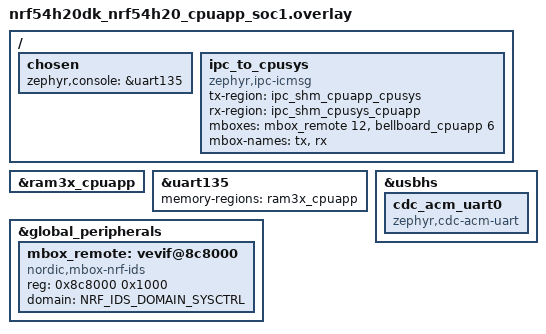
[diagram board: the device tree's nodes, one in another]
/*
 * Copyright (c) 2022 Nordic Semiconductor ASA
 *
 * SPDX-License-Identifier: LicenseRef-BSD-5-Clause-Nordic
 */

#include <common/nordic_nrf_next/nrfx_ram3x_dma.dtsi>

/{
	chosen {
		zephyr,console = &uart135;
	};

	ipc_to_cpusys: ipc_to_cpusys {
		compatible = "zephyr,ipc-icmsg";
		tx-region = <&ipc_shm_cpuapp_cpusys>;
		rx-region = <&ipc_shm_cpusys_cpuapp>;
		mboxes = <&mbox_remote 12>,
			 <&bellboard_cpuapp 6>;
		mbox-names = "tx", "rx";
		status = "okay";
	};
};

&ram3x_cpuapp {
	status = "okay";
};

&uart135 {
	status = "okay";
	memory-regions = <&ram3x_cpuapp>;
};

&global_peripherals {
	/delete-node/ vevif@8c8000;
	/delete-node/ vevif@8d4000;
	/delete-node/ vevif@908000;

	mbox_remote: vevif@8c8000 {
		compatible = "nordic,mbox-nrf-ids";
		reg = <0x8c8000 0x1000>;
		domain = <NRF_IDS_DOMAIN_SYSCTRL>;
		status = "okay";
		#mbox-cells = <1>;
	};
};

zephyr_udc0: &usbhs {
	status = "okay";

	cdc_acm_uart0 {
		compatible = "zephyr,cdc-acm-uart";
	};
};
